# EAM_0.2 register map
Vendor: Texas Instruments
Peripheral module from a debugger description file (folder mspm33c321x).
Registers are 32-bit, read-only, no defined reset value unless marked. A register's access mark holds for its fields unless they carry their own. Offsets are as the file gives them; lines under a group give offsets from that group; [hi:lo] are bit positions; {n}, {i} and the like mark numbered series; 'fields as' and 'values as' point back to an identical list; <NAME> marks a mode.

## EAM
0x1000 EAM_REVISION — IP revision id register
  [0] REVISION — Revisoin register
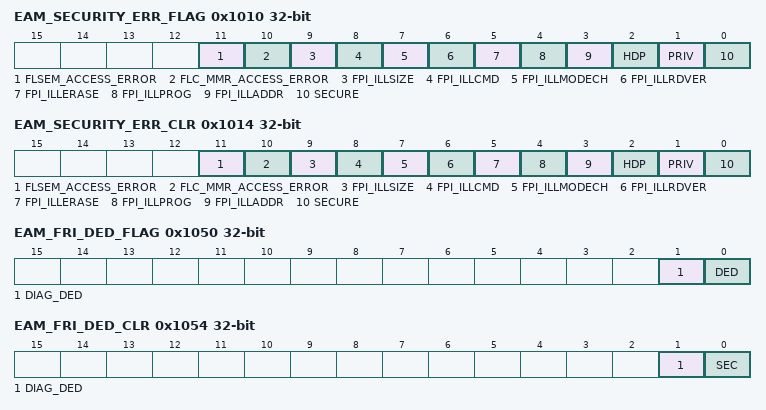
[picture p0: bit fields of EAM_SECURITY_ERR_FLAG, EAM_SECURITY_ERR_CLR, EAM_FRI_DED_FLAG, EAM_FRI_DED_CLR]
0x1010 EAM_SECURITY_ERR_FLAG — Security error flag
  [11] FLSEM_ACCESS_ERROR — FLSEM ACCESS ERROR flag
  [10] FLC_MMR_ACCESS_ERROR — FLC MMR ACCESS ERROR flag
  [9] FPI_ILLSIZE — FPI ILLSIZE flag
  [8] FPI_ILLCMD — FPI ILLCMD flag
  [7] FPI_ILLMODECH — FPI ILLMODECH flag
  [6] FPI_ILLRDVER — FPI ILLRDVER flag
  [5] FPI_ILLERASE — FPI ILLERASE flag
  [4] FPI_ILLPROG — FPI ILLPROG flag
  [3] FPI_ILLADDR — FPI ILLADDR flag
  [2] HDP — Hide protection error flag
  [1] PRIV — Privilege error flag
  [0] SECURE — Secure error flag
0x1014 EAM_SECURITY_ERR_CLR rw — Security error clear
  [11] FLSEM_ACCESS_ERROR — writing '1' will clear SECURITY_ERR_FLAG[FLSEM_ACCESS_ERROR] register.
  [10] FLC_MMR_ACCESS_ERROR — writing '1' will clear SECURITY_ERR_FLAG[FLC_MMR_ACCESS_ERROR] register.
  [9] FPI_ILLSIZE — writing '1' will clear SECURITY_ERR_FLAG[FPI_ILLSIZE] register.
  [8] FPI_ILLCMD — writing '1' will clear SECURITY_ERR_FLAG[FPI_ILLCMD] register.
  [7] FPI_ILLMODECH — writing '1' will clear SECURITY_ERR_FLAG[FPI_ILLMODECH] register.
  [6] FPI_ILLRDVER — writing '1' will clear SECURITY_ERR_FLAG[FPI_ILLRDVER] register.
  [5] FPI_ILLERASE — writing '1' will clear SECURITY_ERR_FLAG[FPI_ILLERASE] register.
  [4] FPI_ILLPROG — writing '1' will clear SECURITY_ERR_FLAG[FPI_ILLPROG] register.
  [3] FPI_ILLADDR — writing '1' will clear SECURITY_ERR_FLAG[FPI_ILLADDR] register.
  [2] HDP — writing '1' will clear SECURITY_ERR_FLAG[HDP] register.
  [1] PRIV — writing '1' will clear SECURITY_ERR_FLAG[PRIV] register.
  [0] SECURE — writing '1' will clear SECURITY_ERR_FLAG[SEC] register.
0x1018 EAM_SECURITY_ERR_MSTID — Security error master id
  [7:0] MSTID — Security error master ID. This field will be cleared along with the corresponding flag clear.
0x101C EAM_SECURITY_ERR_ADDR access not given — Security error address
0x1030 EAM_FRI_SEC_FLAG — FRI SEC flag
  [0] SEC — Single error correction error
0x1034 EAM_FRI_SEC_CLR rw — FRI SEC clear
  [0] SEC — writing '1' will clear FRI_SEC_FLAG[SEC] register.
0x1038 EAM_FRI_SEC_ADDR access not given — FRI SEC address
0x103C EAM_FRI_SEC_MSTID — FRI SEC master id
  [7:0] MSTID — Single error correction error master ID. This field will be cleared along with the corresponding flag clear.
0x1050 EAM_FRI_DED_FLAG — FRI DED flag
  [1] DIAG_DED — diagnostic Double error detect error
  [0] DED — Double error detect error
0x1054 EAM_FRI_DED_CLR rw — FRI DED clear
  [1] DIAG_DED — writing '1' will clear FRI_DED_FLAG[DIAG_DED] register.
  [0] SEC — writing '1' will clear FRI_DED_FLAG[DED] register.
0x1058 EAM_FRI_DED_ADDR access not given — FRI DED address
0x105C EAM_FRI_DED_MSTID — FRI DED master id
  fields as EAM_FRI_SEC_MSTID
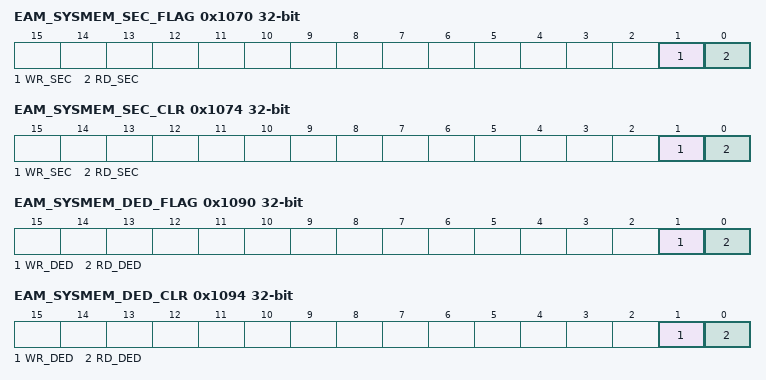
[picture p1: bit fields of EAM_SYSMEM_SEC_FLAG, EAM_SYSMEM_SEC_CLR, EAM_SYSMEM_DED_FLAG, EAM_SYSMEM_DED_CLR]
0x1070 EAM_SYSMEM_SEC_FLAG — SYSMEM SEC flag
  [1] WR_SEC — diagnostic single error correction error during write
  [0] RD_SEC — Single error correction error during read
0x1074 EAM_SYSMEM_SEC_CLR rw — SYSMEM SEC clear
  [1] WR_SEC — writing '1' will clear SYSMEM_SEC_FLAG[WR_SEC] register.
  [0] RD_SEC — writing '1' will clear SYSMEM_SEC_FLAG[RD_SEC] register.
0x1078 EAM_SYSMEM_SEC_ADDR access not given — SYSMEM SEC address
0x107C EAM_SYSMEM_SEC_MSTID — SYSMEM SEC master id
  fields as EAM_FRI_SEC_MSTID
0x1090 EAM_SYSMEM_DED_FLAG — SYSMEM DED flag
  [1] WR_DED — diagnostic Double error detect error during write
  [0] RD_DED — Double error detect error during read
0x1094 EAM_SYSMEM_DED_CLR rw — SYSMEM DED clear
  [1] WR_DED — writing '1' will clear SYSMEM_DED_FLAG[WR_DED] register.
  [0] RD_DED — writing '1' will clear SYSMEM_DED_FLAG[RD_DED] register.
0x1098 EAM_SYSMEM_DED_ADDR access not given — SYSMEM DED address
0x109C EAM_SYSMEM_DED_MSTID — SYSMEM DED master id
  fields as EAM_FRI_SEC_MSTID
